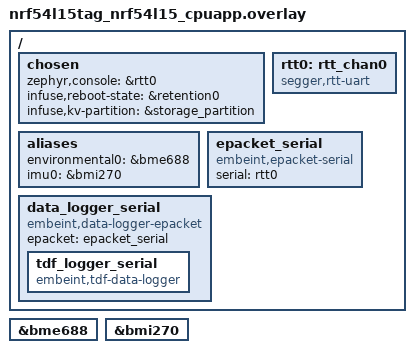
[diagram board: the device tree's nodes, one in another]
/*
 * Copyright (c) 2026 Embeint Holdings Pty Ltd
 * SPDX-License-Identifier: FSL-1.1-ALv2
 */

#include <common/nordic/infuse_nrf54l15_cpuapp.dtsi>
#include <common/infuse_bluetooth.dtsi>

/ {
	chosen {
		zephyr,console = &rtt0;
		infuse,reboot-state = &retention0;
		infuse,kv-partition = &storage_partition;
	};

	rtt0: rtt_chan0 {
		compatible = "segger,rtt-uart";
		status = "okay";
	};

	aliases {
		environmental0 = &bme688;
		imu0 = &bmi270;
	};
};

#ifndef INFUSE_IS_BOOTLOADER

&bme688 {
	status = "okay";
};

&bmi270 {
	status = "okay";
};

/ {
	epacket_serial: epacket_serial {
		compatible = "embeint,epacket-serial";
		serial = <&rtt0>;
	};

	data_logger_serial: data_logger_serial {
		compatible = "embeint,data-logger-epacket", "embeint,data-logger";
		epacket = <&epacket_serial>;

		tdf_logger_serial: tdf_logger_serial {
			compatible = "embeint,tdf-data-logger";
		};
	};
};

#endif /* !INFUSE_IS_BOOTLOADER */
